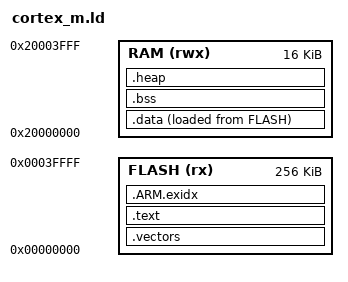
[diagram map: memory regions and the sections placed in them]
/* Cortex-M freestanding linker script -- micro:bit (nRF51): 256K flash,
 * 16K RAM. For a different board, copy this file, adjust MEMORY, and pass
 * it with `--linker-script <path>` (bring-your-own-linker-script contract).
 *
 * Copyright (c) 2026 Eleftherios Notas and The XIOM Authors
 * SPDX-License-Identifier: MIT OR Apache-2.0
 */

ENTRY(Reset_Handler)

MEMORY
{
    FLASH (rx)  : ORIGIN = 0x00000000, LENGTH = 256K
    RAM   (rwx) : ORIGIN = 0x20000000, LENGTH = 16K
}

SECTIONS
{
    .vectors :
    {
        KEEP(*(.vectors))
    } > FLASH

    .text :
    {
        *(.text*)
        *(.rodata*)
    } > FLASH

    .ARM.exidx :
    {
        *(.ARM.exidx*)
    } > FLASH

    .data :
    {
        __data_start = .;
        *(.data*)
        __data_end = .;
    } > RAM AT > FLASH
    __data_load = LOADADDR(.data);

    .bss (NOLOAD) :
    {
        __bss_start = .;
        *(.bss*)
        *(COMMON)
        __bss_end = .;
    } > RAM

    .heap (NOLOAD) :
    {
        . = ALIGN(8);
        __heap_start = .;
        . = . + 0x400;
        __heap_end = .;
    } > RAM

    _estack = ORIGIN(RAM) + LENGTH(RAM);
}
